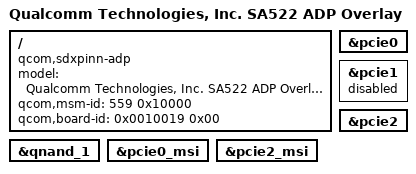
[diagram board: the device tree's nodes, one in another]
/dts-v1/;
/plugin/;

#include "sa522m-adp.dtsi"

/ {
	model = "Qualcomm Technologies, Inc. SA522 ADP Overlay";
	compatible = "qcom,sdxpinn-adp",
		"qcom,sdxpinn", "qcom,adp";
	qcom,msm-id=<559 0x10000>;
	qcom,board-id = <0x0010019 0x00>;
};

&qnand_1 {
	status = "ok";
};

&pcie0 {
	status = "ok";
};

&pcie0_msi {
	status = "ok";
};

&pcie1 {
	status = "disabled";
};

&pcie2 {
	status = "ok";
};

&pcie2_msi {
	status = "ok";
};
